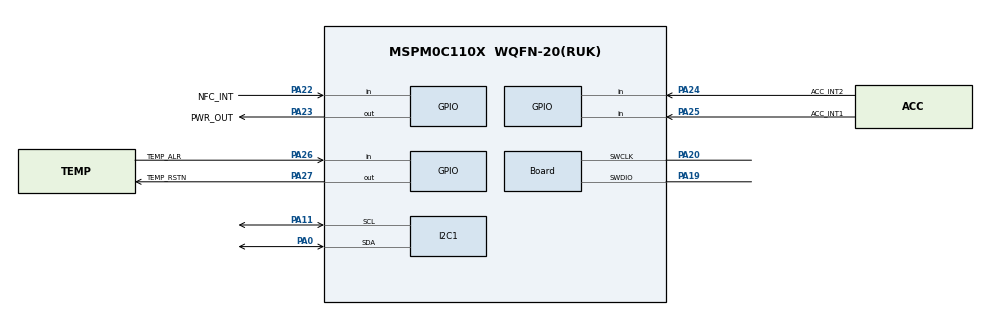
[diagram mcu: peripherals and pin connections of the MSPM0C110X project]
/**
 * @cliArgs --device "MSPM0C110X" --part "Default" --package "WQFN-20(RUK)" --product "mspm0_sdk@2.09.00.02"
 * @versions {"tool":"1.25.0+4268"}
 */

/**
 * Import the modules used in this configuration.
 */
const GPIO   = scripting.addModule("/ti/driverlib/GPIO", {}, false);
const GPIO1  = GPIO.addInstance();
const I2C    = scripting.addModule("/ti/driverlib/I2C", {}, false);
const I2C1   = I2C.addInstance();
const SYSCTL = scripting.addModule("/ti/driverlib/SYSCTL");

/**
 * Write custom configuration values to the imported modules.
 */
GPIO1.$name                               = "GROUP0";
GPIO1.port                                = "PORTA";
GPIO1.associatedPins.create(6);
GPIO1.associatedPins[0].direction         = "INPUT";
GPIO1.associatedPins[0].interruptEn       = true;
GPIO1.associatedPins[0].interruptPriority = "1";
GPIO1.associatedPins[0].polarity          = "FALL";
GPIO1.associatedPins[0].$name             = "NFC_INT";
GPIO1.associatedPins[0].pin.$assign       = "PA22";
GPIO1.associatedPins[1].$name             = "PWR_OUT";
GPIO1.associatedPins[1].pin.$assign       = "PA23";
GPIO1.associatedPins[2].$name             = "ACC_INT2";
GPIO1.associatedPins[2].direction         = "INPUT";
GPIO1.associatedPins[2].interruptEn       = true;
GPIO1.associatedPins[2].interruptPriority = "1";
GPIO1.associatedPins[2].polarity          = "FALL";
GPIO1.associatedPins[2].internalResistor  = "PULL_UP";
GPIO1.associatedPins[2].pin.$assign       = "PA24";
GPIO1.associatedPins[3].$name             = "ACC_INT1";
GPIO1.associatedPins[3].direction         = "INPUT";
GPIO1.associatedPins[3].internalResistor  = "PULL_UP";
GPIO1.associatedPins[3].interruptEn       = true;
GPIO1.associatedPins[3].interruptPriority = "1";
GPIO1.associatedPins[3].polarity          = "FALL";
GPIO1.associatedPins[3].pin.$assign       = "PA25";
GPIO1.associatedPins[4].$name             = "TEMP_ALR";
GPIO1.associatedPins[4].direction         = "INPUT";
GPIO1.associatedPins[4].internalResistor  = "PULL_UP";
GPIO1.associatedPins[4].interruptEn       = true;
GPIO1.associatedPins[4].interruptPriority = "1";
GPIO1.associatedPins[4].polarity          = "FALL";
GPIO1.associatedPins[4].pin.$assign       = "PA26";
GPIO1.associatedPins[5].$name             = "TEMP_RSTN";
GPIO1.associatedPins[5].initialValue      = "SET";
GPIO1.associatedPins[5].pin.$assign       = "PA27";

const Board                       = scripting.addModule("/ti/driverlib/Board", {}, false);
Board.peripheral.$assign          = "DEBUGSS";
Board.peripheral.swclkPin.$assign = "PA20";
Board.peripheral.swdioPin.$assign = "PA19";

I2C1.basicEnableController             = true;
I2C1.advControllerTXFIFOTRIG           = "BYTES_1";
I2C1.$name                             = "I2C";
I2C1.peripheral.$assign                = "I2C0";
I2C1.peripheral.sdaPin.$assign         = "PA0";
I2C1.peripheral.sclPin.$assign         = "PA11";
I2C1.sdaPinConfig.$name                = "ti_driverlib_gpio_GPIOPinGeneric0";
I2C1.sdaPinConfig.hideOutputInversion  = scripting.forceWrite(false);
I2C1.sdaPinConfig.onlyInternalResistor = scripting.forceWrite(false);
I2C1.sdaPinConfig.passedPeripheralType = scripting.forceWrite("Digital");
I2C1.sclPinConfig.$name                = "ti_driverlib_gpio_GPIOPinGeneric1";
I2C1.sclPinConfig.hideOutputInversion  = scripting.forceWrite(false);
I2C1.sclPinConfig.onlyInternalResistor = scripting.forceWrite(false);
I2C1.sclPinConfig.passedPeripheralType = scripting.forceWrite("Digital");

SYSCTL.peripheral.$assign = "SYSCTL";

const ProjectConfig              = scripting.addModule("/ti/project_config/ProjectConfig", {}, false);
ProjectConfig.migrationCondition = true;
